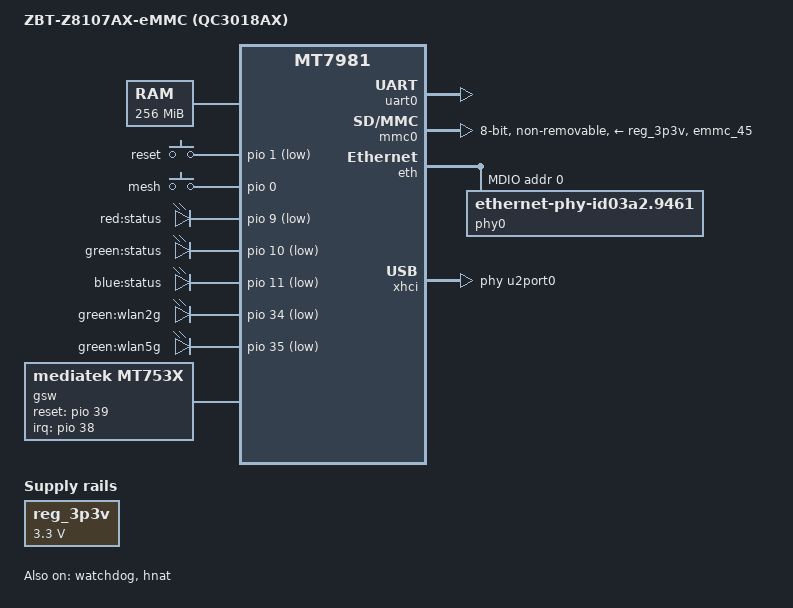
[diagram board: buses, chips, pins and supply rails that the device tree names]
// SPDX-License-Identifier: GPL-2.0-or-later OR MIT
/*
 * Copyright (C) 2023 Tianling Shen <cnsztl@immortalwrt.org>
 */

/dts-v1/;
#include <dt-bindings/gpio/gpio.h>
#include <dt-bindings/input/input.h>

#include "mt7981.dtsi"

/ {
	model = "ZBT-Z8107AX-eMMC (QC3018AX)";
	compatible = "zbtlink,z8107ax-emmc", "mediatek,mt7981";

	aliases {
		led-boot = &led_status_red;
		led-failsafe = &led_status_red;
		led-running = &led_status_green;
		led-upgrade = &led_status_green;
	};

	chosen {
		bootargs = "console=ttyS0,115200n1 loglevel=8  \
				earlycon=uart8250,mmio32,0x11002000 \
				root=PARTLABEL=rootfs rootfstype=squashfs,f2fs";
	};

	memory {
		reg = <0 0x40000000 0 0x10000000>;
	};

	gpio-keys {
		compatible = "gpio-keys";

		button-reset {
			label = "reset";
			linux,code = <KEY_RESTART>;
			gpios = <&pio 1 GPIO_ACTIVE_LOW>;
		};

		button-mesh {
			label = "mesh";
			linux,code = <BTN_9>;
			linux,input-type = <EV_SW>;
			gpios = <&pio 0 GPIO_ACTIVE_HIGH>;
		};
	};

	gpio-leds {
		compatible = "gpio-leds";

		led_status_red:led-0 {
			label = "red:status";
			gpios = <&pio 9 GPIO_ACTIVE_LOW>;
		};

		led_status_green:led-1 {
			label = "green:status";
			gpios = <&pio 10 GPIO_ACTIVE_LOW>;
		};

		led_status_blue:led-2 {
			label = "blue:status";
			gpios = <&pio 11 GPIO_ACTIVE_LOW>;
		};

		led-wlan2g {
			label = "green:wlan2g";
			gpios = <&pio 34 GPIO_ACTIVE_LOW>;
		};

		led-wlan5g {
			label = "green:wlan5g";
			gpios = <&pio 35 GPIO_ACTIVE_LOW>;
		};
	};

	reg_3p3v: regulator-3p3v {
		compatible = "regulator-fixed";
		regulator-name = "fixed-3.3V";
		regulator-min-microvolt = <3300000>;
		regulator-max-microvolt = <3300000>;
		regulator-boot-on;
		regulator-always-on;
	};

	gsw: gsw@0 {
		compatible = "mediatek,mt753x";
		mediatek,ethsys = <&ethsys>;
		#address-cells = <1>;
		#size-cells = <0>;
	};
};

&uart0 {
	status = "okay";
};

&watchdog {
	status = "okay";
};

&mmc0 {
         pinctrl-names = "default", "state_uhs";
         pinctrl-0 = <&mmc0_pins_default>;
         pinctrl-1 = <&mmc0_pins_uhs>;
         bus-width = <8>;
         max-frequency = <52000000>;
         cap-mmc-highspeed;
         vmmc-supply = <&reg_3p3v>;
         non-removable;
         status = "okay";
};

&eth {
	status = "okay";

	gmac0: mac@0 {
		compatible = "mediatek,eth-mac";
		reg = <0>;
		phy-mode = "2500base-x";

		fixed-link {
			speed = <2500>;
			full-duplex;
			pause;
		};
	};

	gmac1: mac@1 {
		compatible = "mediatek,eth-mac";
		reg = <1>;
		label = "wan";
		phy-mode = "gmii";
		phy-handle = <&phy0>;
	};

	mdio: mdio-bus {
		#address-cells = <1>;
		#size-cells = <0>;

		phy0: ethernet-phy@0 {
			compatible = "ethernet-phy-id03a2.9461";
			reg = <0>;
			phy-mode = "gmii";
			nvmem-cells = <&phy_calibration>;
			nvmem-cell-names = "phy-cal-data";
		};
	};
};

&gsw {
	mediatek,mdio = <&mdio>;
	mediatek,portmap = "wllll";
	mediatek,mdio_master_pinmux = <0>;
	reset-gpios = <&pio 39 0>;
	interrupt-parent = <&pio>;
	interrupts = <38 IRQ_TYPE_LEVEL_HIGH>;
	status = "okay";

	port6: port@6 {
		compatible = "mediatek,mt753x-port";
		mediatek,ssc-on;
		reg = <6>;
		phy-mode = "sgmii";

		fixed-link {
			speed = <2500>;
			full-duplex;
		};
	};
};

&hnat {
        mtketh-wan = "eth1";
        mtketh-lan = "eth0";
        mtketh-max-gmac = <2>;
        status = "okay";
};

&spi1 {
	pinctrl-names = "default";
	pinctrl-0 = <&spic_pins>;
	status = "disabled";
};

&pio {

	spic_pins: spi1-pins {
		mux {
			function = "spi";
			groups = "spi1_1";
		};
	};

	mmc0_pins_default: mmc0-pins-default {
		mux {
			function = "flash";
			groups = "emmc_45";
		};
	};

	mmc0_pins_uhs: mmc0-pins-uhs {
		mux {
			function = "flash";
			groups = "emmc_45";
		};
	};
};

&xhci {
	mediatek,u3p-dis-msk = <0x0>;
	phys = <&u2port0 PHY_TYPE_USB2>,
	       <&u3port0 PHY_TYPE_USB3>;
	status = "okay";
};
